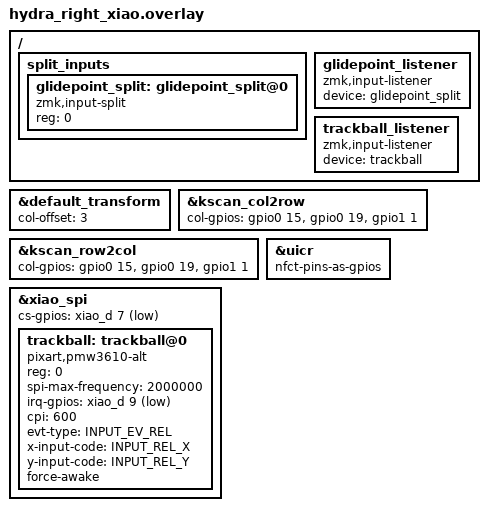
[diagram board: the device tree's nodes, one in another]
#include "hydra_xiao.dtsi"
#include <zephyr/dt-bindings/input/input-event-codes.h>

&default_transform { col-offset = <3>; };

/* ── COL1-3: XIAO Plus D11-D13 (P0.15/P0.19/P1.01) ── */
&kscan_col2row {
    col-gpios
        = <&gpio0 15 GPIO_ACTIVE_HIGH>  // COL1 D11/P0.15
        , <&gpio0 19 GPIO_ACTIVE_HIGH>  // COL2 D12/P0.19
        , <&gpio1  1 GPIO_ACTIVE_HIGH>  // COL3 D13/P1.01
        ;
};

&kscan_row2col {
    col-gpios
        = <&gpio0 15 (GPIO_ACTIVE_HIGH | GPIO_PULL_DOWN)>  // COL1 D11/P0.15
        , <&gpio0 19 (GPIO_ACTIVE_HIGH | GPIO_PULL_DOWN)>  // COL2 D12/P0.19
        , <&gpio1  1 (GPIO_ACTIVE_HIGH | GPIO_PULL_DOWN)>  // COL3 D13/P1.01
        ;
};

/* ── Unlock NFC pins P0.09/P0.10 for OLED CS/DC GPIO ── */
&uicr {
    nfct-pins-as-gpios;
};

/* ── SPI PMW3610: board xiao_spi already has pinctrl for D8/D9/D10 ── */
&xiao_spi {
    status = "okay";
    cs-gpios = <&xiao_d 7 GPIO_ACTIVE_LOW>;  // D7/P1.12 NCS

    trackball: trackball@0 {
        compatible = "pixart,pmw3610-alt";
        status = "okay";
        reg = <0>;
        spi-max-frequency = <2000000>;
        irq-gpios = <&xiao_d 9 (GPIO_ACTIVE_LOW | GPIO_PULL_UP)>;  // D9/P1.14 MOT
        cpi = <600>;
        evt-type = <INPUT_EV_REL>;
        x-input-code = <INPUT_REL_X>;
        y-input-code = <INPUT_REL_Y>;
        force-awake;
    };
};

/ {
    split_inputs {
        #address-cells = <1>;
        #size-cells = <0>;

        glidepoint_split: glidepoint_split@0 {
            compatible = "zmk,input-split";
            reg = <0>;
        };
    };

    glidepoint_listener: glidepoint_listener {
        compatible = "zmk,input-listener";
        device = <&glidepoint_split>;
    };

    trackball_listener: trackball_listener {
        compatible = "zmk,input-listener";
        device = <&trackball>;
    };
};
